# UC13_2_1.0 register map
Vendor: Texas Instruments
Peripheral module from a debugger description file (folder mspm33c321x).
Registers are 32-bit, read-write, no defined reset value unless marked. A register's access mark holds for its fields unless they carry their own. Offsets are as the file gives them; lines under a group give offsets from that group; [hi:lo] are bit positions; {n}, {i} and the like mark numbered series; 'fields as' and 'values as' point back to an identical list; <NAME> marks a mode.

## UC13_2
0x800 UC13_2_GPRCM group
  0x00 UC13_2_PWREN — Power enable
    [0] ENABLE — Enable the power
      0=DISABLE (Disable Power); 1=ENABLE (Enable Power)
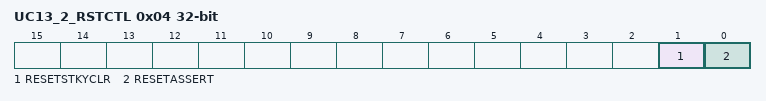
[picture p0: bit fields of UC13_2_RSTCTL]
  0x04 UC13_2_RSTCTL — Reset Control
    [1] RESETSTKYCLR — Clear the RESETSTKY bit in the STAT register
      0=NOP (Writing 0 has no effect); 1=CLR (Clear reset sticky bit)
    [0] RESETASSERT — Assert reset to the peripheral
      0=NOP (Writing 0 has no effect); 1=ASSERT (Assert reset)
  0x08 UC13_2_CLKCFG — Peripheral Clock Configuration Register
    [8] BLOCKASYNC — Async Clock Request is blocked from starting SYSOSC or forcing bus clock to 32MHz
      0=DISABLE (Not block async clock request); 1=ENABLE (Block async clock request)
  0x14 UC13_2_GPRCM_STAT ro — Status Register
    [16] RESETSTKY — This bit indicates, if the peripheral was reset, since this bit was cleared by RESETSTKYCLR in the RSTCTL register
      0=NORES (The peripheral has not been reset since this bit was last cleared by RESETSTKYCLR in the RSTCTL register); 1=RESET (The peripheral was reset since the last bit clear)
0x1100 UC13_2_IPMODE — Mode Selection Register
  [1:0] SELECT — Free run control
    0=UART (Default functionality is UART); 1=SPI (SPG in SPI Mode); 2=I2C_CONTROLLER (SPG in I2C Controller Mode); 3=I2C_PERIPHERAL (SPG in I2C Peripheral Mode)
